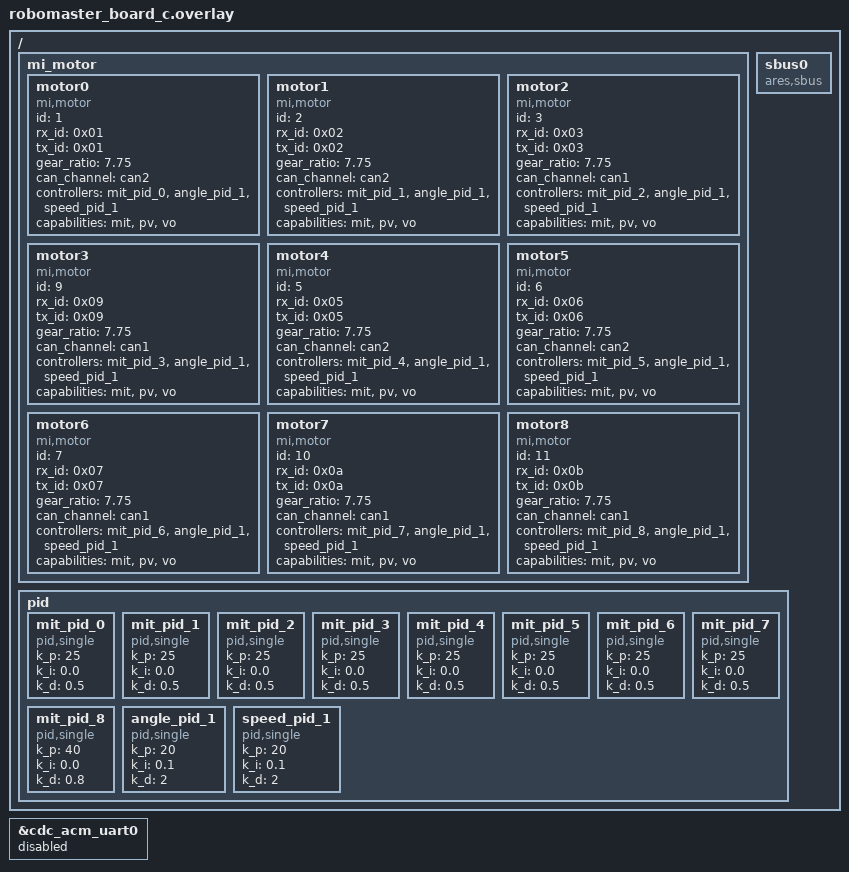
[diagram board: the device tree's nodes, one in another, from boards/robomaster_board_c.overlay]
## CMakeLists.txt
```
# SPDX-License-Identifier: Apache-2.0

cmake_minimum_required(VERSION 3.20.0)
set(CMAKE_CXX_STANDARD 17)
find_package(Zephyr REQUIRED HINTS $ENV{ZEPHYR_BASE})
project(legged)

FILE(GLOB app_sources src/*.c)

include_directories(${ZEPHYR_BASE}/include)
include_directories(${CMAKE_CURRENT_SOURCE_DIR}/include)
include_directories(${CMAKE_CURRENT_SOURCE_DIR}/dts)
target_sources(app PRIVATE ${app_sources})
target_include_directories(app PRIVATE ${ZEPHYR_BASE}/include)
target_include_directories(app PRIVATE ${CMAKE_CURRENT_SOURCE_DIR}/include)
target_include_directories(app PRIVATE ${CMAKE_CURRENT_SOURCE_DIR}/dts)
```

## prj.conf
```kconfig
#启用线程分析器
CONFIG_THREAD_ANALYZER=y
CONFIG_THREAD_ANALYZER_USE_LOG=y
CONFIG_THREAD_ANALYZER_USE_PRINTK=n
CONFIG_THREAD_NAME=y
# CONFIG_THREAD_ANALYZER_AUTO=y
# CONFIG_THREAD_ANALYZER_AUTO_INTERVAL=5
# CONFIG_THREAD_ANALYZER_LOG_LEVEL_INF=y
# CONFIG_THREAD_ANALYZER_AUTO_SEPARATE_CORES=n

# 启用 UART 控制台
CONFIG_UART_CONSOLE=y

# 禁用 SEGGER RTT
CONFIG_USE_SEGGER_RTT=n

# 启用事件支持
CONFIG_EVENTS=y

# 启用串行支持
CONFIG_SERIAL=y
CONFIG_SPI_ASYNC=y
# 禁用优化
CONFIG_NO_OPTIMIZATIONS=n

# 启用驱动
CONFIG_MOTOR=y
CONFIG_MOTOR_DJI=y
CONFIG_MOTOR_MI=y
CONFIG_MOTOR_LOG_LEVEL=4
CONFIG_CAN=y
CONFIG_MOTOR_INIT_PRIORITY=90
CONFIG_PID=y

CONFIG_ARES=y
CONFIG_ARES_SBUS=y
CONFIG_SBUS_INIT_PRIORITY=90

CONFIG_DMA=y
CONFIG_DMA_STM32=y  # STM32 DMA 驱动
CONFIG_UART_STM32=y # STM32 UART 驱动
# CONFIG_STM32_UART_DMA=y
CONFIG_AUTO_PROBE_GYRO_BIAS=y
CONFIG_EKF_LIB=y
# CONFIG_HAS_STM32CUBE=y
# CONFIG_USE_STM32_HAL_DMA=y
# CONFIG_SPI=y
# CONFIG_SPI_STM32=y

#
# Device Drivers
#
# CONFIG_SENSOR=y
# CONFIG_BMI08X=y
# CONFIG_BMI08X_ACCEL_TRIGGER_NONE is not set
# CONFIG_BMI08X_ACCEL_TRIGGER_GLOBAL_THREAD=y
# CONFIG_BMI08X_ACCEL_TRIGGER_OWN_THREAD is not set
# CONFIG_BMI08X_GYRO_TRIGGER_NONE is not set
# CONFIG_BMI08X_GYRO_TRIGGER_GLOBAL_THREAD=y
# CONFIG_BMI08X_GYRO_TRIGGER_OWN_THREAD is not set
# CONFIG_BMI08X_I2C_WRITE_BURST_SIZE=16

CONFIG_DEBUG_THREAD_INFO=y
CONFIG_MAIN_STACK_SIZE=4096

# ARES communication libraries
# CONFIG_EXPERIMENTAL_BULK_LIB=y
CONFIG_USB_BULK_INTERFACE=y
CONFIG_DUAL_PROPOSE_PROTOCOL=y

CONFIG_UDC_DRIVER_LOG_LEVEL_WRN=y
CONFIG_USBD_LOG_LEVEL_WRN=y

CONFIG_USBD_MAX_UDC_MSG=24
CONFIG_USBD_MSG_SLAB_COUNT=24
CONFIG_UDC_BUF_COUNT=128
CONFIG_UDC_WORKQUEUE=y
CONFIG_UDC_WORKQUEUE_PRIORITY=0
CONFIG_UDC_BUF_POOL_SIZE=4096
# Enable legacy USB device stack (provides usb_dc_ep_write)
# CONFIG_USB_DEVICE_STACK=y
# Set VID/PID for device; optional but good practice
# CONFIG_USB_DEVICE_VID=0x1209
# CONFIG_USB_DEVICE_PID=0x0001
```

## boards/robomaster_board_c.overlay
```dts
/ {
	mi_motor {
		motor0: motor0{
			compatible = "mi,motor";
			id = <1>;
			rx_id = <0x01>;
			tx_id = <0x01>;
			gear_ratio = "7.75";
			status = "okay";
			can_channel = <&can2>;
			controllers = <&mit_pid_0 &angle_pid_1 &speed_pid_1>;
			capabilities = "mit","pv", "vo";
		};

		motor1: motor1{
			compatible = "mi,motor";
			id = <2>;
			rx_id = <0x02>;
			tx_id = <0x02>;
			gear_ratio = "7.75";
			status = "okay";
			can_channel = <&can2>;
			controllers = <&mit_pid_1 &angle_pid_1 &speed_pid_1>;
			capabilities = "mit","pv", "vo";
		};

		motor2: motor2{
			compatible = "mi,motor";
			id = <3>;
			rx_id = <0x03>;
			tx_id = <0x03>;
			gear_ratio = "7.75";
			status = "okay";
			can_channel = <&can1>;
			controllers = <&mit_pid_2 &angle_pid_1 &speed_pid_1>;
			capabilities = "mit","pv", "vo";
		};

		motor3: motor3{
			compatible = "mi,motor";
			id = <9>;
			rx_id = <0x09>;
			tx_id = <0x09>;
			gear_ratio = "7.75";
			status = "okay";
			can_channel = <&can1>;
			controllers = <&mit_pid_3 &angle_pid_1 &speed_pid_1>;
			capabilities = "mit","pv", "vo";
		};
		
		motor4: motor4{
			compatible = "mi,motor";
			id = <5>;
			rx_id = <0x05>;
			tx_id = <0x05>;
			gear_ratio = "7.75";
			status = "okay";
			can_channel = <&can2>;
			controllers = <&mit_pid_4 &angle_pid_1 &speed_pid_1>;
			capabilities = "mit","pv", "vo";
		};

		motor5: motor5{
			compatible = "mi,motor";
			id = <6>;
			rx_id = <0x06>;
			tx_id = <0x06>;
			gear_ratio = "7.75";
			status = "okay";
			can_channel = <&can2>;
			controllers = <&mit_pid_5 &angle_pid_1 &speed_pid_1>;
			capabilities = "mit","pv", "vo";
		};

		motor6: motor6{
			compatible = "mi,motor";
			id = <7>;
			rx_id = <0x07>;
			tx_id = <0x07>;
			gear_ratio = "7.75";
			status = "okay";
			can_channel = <&can1>;
			controllers = <&mit_pid_6 &angle_pid_1 &speed_pid_1>;
			capabilities = "mit","pv", "vo";
		};

		motor7: motor7{
			compatible = "mi,motor";
			id = <10>;
			rx_id = <0x0a>;
			tx_id = <0x0a>;
			gear_ratio = "7.75";
			status = "okay";
			can_channel = <&can1>;
			controllers = <&mit_pid_7 &angle_pid_1 &speed_pid_1>;
			capabilities = "mit","pv", "vo";
		};
		motor8: motor8{
			compatible = "mi,motor";
			id = <11>;
			rx_id = <0x0b>;
			tx_id = <0x0b>;
			gear_ratio = "7.75";
			status = "okay";
			can_channel = <&can1>;
			controllers = <&mit_pid_8 &angle_pid_1 &speed_pid_1>;
			capabilities = "mit","pv", "vo";
		};
	};
	sbus0: sbus0 {
		compatible = "ares,sbus";
		status = "okay";
	};
	pid {
		mit_pid_0: mit_pid_0 {
			#controller-cells = <0>;
			compatible = "pid,single";
			k_p = "25";
			k_i = "0.0";
			k_d = "0.5";
		};
		mit_pid_1: mit_pid_1 {
			#controller-cells = <0>;
			compatible = "pid,single";
			k_p = "25";
			k_i = "0.0";
			k_d = "0.5";
		};
		mit_pid_2: mit_pid_2 {
			#controller-cells = <0>;
			compatible = "pid,single";
			k_p = "25";
			k_i = "0.0";
			k_d = "0.5";
		};
		mit_pid_3: mit_pid_3 {
			#controller-cells = <0>;
			compatible = "pid,single";
			k_p = "25";
			k_i = "0.0";
			k_d = "0.5";
		};
		mit_pid_4: mit_pid_4 {
			#controller-cells = <0>;
			compatible = "pid,single";
			k_p = "25";
			k_i = "0.0";
			k_d = "0.5";
		};
		mit_pid_5: mit_pid_5 {
			#controller-cells = <0>;
			compatible = "pid,single";
			k_p = "25";
			k_i = "0.0";
			k_d = "0.5";
		};
		mit_pid_6: mit_pid_6 {
			#controller-cells = <0>;
			compatible = "pid,single";
			k_p = "25";
			k_i = "0.0";
			k_d = "0.5";
		};
		mit_pid_7: mit_pid_7 {
			#controller-cells = <0>;
			compatible = "pid,single";
			k_p = "25";
			k_i = "0.0";
			k_d = "0.5";
		};
		mit_pid_8: mit_pid_8 {
			#controller-cells = <0>;
			compatible = "pid,single";
			k_p = "40";
			k_i = "0.0";
			k_d = "0.8";
		};
		
		angle_pid_1: angle_pid_1 {
			#controller-cells = <0>;
			compatible = "pid,single";
			k_p = "20";
			k_i = "0.1";
			k_d = "2";
		};
		speed_pid_1: speed_pid_1 {
			#controller-cells = <0>;
			compatible = "pid,single";
			k_p = "20";
			k_i = "0.1";
			k_d = "2";
		};
	};
};

&cdc_acm_uart0 {
	status = "disabled";
};
```

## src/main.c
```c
#include <math.h>
#include <stdbool.h>
#include <stddef.h>
#include <stdint.h>
#include <zephyr/device.h>
#include <zephyr/logging/log.h>
#include <zephyr/kernel.h>
#include <zephyr/drivers/motor.h>
#include <zephyr/drivers/sbus.h>
#include <ares/board/init.h>
#include <ares/ekf/imu_task.h>
#include <ares/ares_comm.h>
#include <ares/protocol/dual/dual_protocol.h>
#include "ares/ekf/QuaternionEKF.h"
#include <zephyr/debug/thread_analyzer.h>
#include <ares/interface/usb/usb_bulk.h>
#include <zephyr/drivers/gpio.h>
#include "main.h"
#include "ares/protocol/dual/dual_protocol.h"

LOG_MODULE_REGISTER(main, LOG_LEVEL_DBG);

#ifndef PI
#define PI 3.14159265358979323846f
#endif

#define STACK_SIZE 4096

#define RPM2RADPS(rpm) ((rpm) * (PI / 30.0f))
#define RADPS2RPM(radps) ((radps) * (30.0f / PI))
#define DEG2RAD(deg) ((deg) * (PI / 180.0f))
#define RAD2DEG(rad) ((rad) * (180.0f / PI))
/**
 * @brief 计算重力向量在地面坐标系中的单位化投影
 * @param q 四元数 [q0, q1, q2, q3] (归一化)
 * @param body_accel 载体坐标系下的加速度 [ax, ay, az]（未使用，保留接口兼容性）
 * @param g 重力加速度大小（未使用，保留接口兼容性）
 * @param gravity_projection 输出：重力向量在地面坐标系的单位化投影 [gx, gy, gz]
 */
void calculate_gravity_projection(float *q, float *body_accel, float g, float *gravity_projection)
{
    // 四元数转旋转矩阵公式
    float q0 = q[0], q1 = q[1], q2 = q[2], q3 = q[3];
    
    // 确保四元数是归一化的
    float qnorm = sqrtf(q0*q0 + q1*q1 + q2*q2 + q3*q3);
    if (qnorm > 0.0001f) {
        q0 /= qnorm; q1 /= qnorm; q2 /= qnorm; q3 /= qnorm;
    }
    
    // 载体坐标系各轴在重力方向上的投影
    // 即载体坐标系XYZ轴与重力向量（垂直向下）的夹角余弦值
    // 这等价于将载体坐标系的单位向量投影到重力方向上
    
    // 载体坐标系X轴在重力方向的投影 = 载体X轴与重力向量的点积
    // 载体X轴: [1,0,0] 变换到地面坐标系，然后与重力向量[0,0,-1]点积
    // 结果就是旋转矩阵第一行第三列的负值
    gravity_projection[0] = -(2 * (q1 * q3 + q0 * q2));  // 载体X轴在重力方向的投影
    
    // 载体坐标系Y轴在重力方向的投影
    gravity_projection[1] = -(2 * (q2 * q3 - q0 * q1));  // 载体Y轴在重力方向的投影
    
    // 载体坐标系Z轴在重力方向的投影  
    gravity_projection[2] = -(1 - 2 * (q1 * q1 + q2 * q2));  // 载体Z轴在重力方向的投影
    
    // 这些值的范围是[-1, 1]，表示各轴与重力方向的夹角余弦值
    // 当载体某轴与重力方向平行时，对应投影为±1
    // 当载体某轴与重力方向垂直时，对应投影为0
}

/**
 * @brief 计算四元数对应的欧拉角
 * @param q 四元数 [q0, q1, q2, q3]
 * @param euler 输出欧拉角 [roll, pitch, yaw] (弧度)
 */
void quaternion_to_euler(float *q, float *euler)
{
    float q0 = q[0], q1 = q[1], q2 = q[2], q3 = q[3];
    
    // Roll (绕X轴旋转)
    euler[0] = atan2f(2.0f * (q0 * q1 + q2 * q3), 1.0f - 2.0f * (q1 * q1 + q2 * q2));
    
    // Pitch (绕Y轴旋转)
    float sin_pitch = 2.0f * (q0 * q2 - q3 * q1);
    if (fabsf(sin_pitch) >= 1.0f) {
        euler[1] = copysignf(PI / 2.0f, sin_pitch); // 万向锁情况
    } else {
        euler[1] = asinf(sin_pitch);
    }
    
    // Yaw (绕Z轴旋转)
    euler[2] = atan2f(2.0f * (q0 * q3 + q1 * q2), 1.0f - 2.0f * (q2 * q2 + q3 * q3));
}
float kp_cmd[9] = {0};
float kd_cmd[9] = {0};
float action[9]= {0};
float torque_cmd[9] = {0};
float motor_angle[9] = {0};
float motor_speed[9] = {0};
float motor_torque[9] = {0};
float imu_pack[10] = {0};
float current_accel[3] = {0};  // 存储当前加速度数据
float sbus_data[11] = {0};
uint8_t actionbuf[36]= {0};
uint8_t torque_cmdbuf[36]= {0};
uint8_t anglebuf[36]= {0};
uint8_t speedbuf[36]= {0};
uint8_t torquebuf[36]= {0};
uint8_t imudatabuf[40]= {0};
uint8_t sbus_buf[44]= {0};
uint8_t kp_cmdbuf[36]= {0};
uint8_t kd_cmdbuf[36]= {0};
sync_table_t *angle_tx;
sync_table_t *speed_tx;
sync_table_t *torque_tx;
sync_table_t *imu_tx;
sync_table_t *sbus_tx;

struct pid_config new_config={.k_p = 25.0f, .k_d = 0.5f};
static int pub_cnt = 0;  // 添加发布计数器

DUAL_PROPOSE_PROTOCOL_DEFINE(dual_protocol);
ARES_BULK_INTERFACE_DEFINE(usb_bulk_interface);

// leg_motors leg1 = { motor1, motor2, LEFT_BACK};
// leg_motors leg2 = { motor3, motor4, LEFT_FRONT};
// leg_motors leg3 = { motor6, motor5, RIGHT_BACK};
// leg_motors leg4 = { motor8, motor7, RIGHT_FRONT};

const struct device *motors[9]={
    DEVICE_DT_GET(DT_NODELABEL(motor3)), DEVICE_DT_GET(DT_NODELABEL(motor2)), DEVICE_DT_GET(DT_NODELABEL(motor6)), DEVICE_DT_GET(DT_NODELABEL(motor7)), DEVICE_DT_GET(DT_NODELABEL(motor8)), DEVICE_DT_GET(DT_NODELABEL(motor1)), DEVICE_DT_GET(DT_NODELABEL(motor0)), DEVICE_DT_GET(DT_NODELABEL(motor4)), DEVICE_DT_GET(DT_NODELABEL(motor5))
};

const struct device *mit_pid[9] ={
    DEVICE_DT_GET(DT_NODELABEL(mit_pid_3)),
    DEVICE_DT_GET(DT_NODELABEL(mit_pid_2)),
    DEVICE_DT_GET(DT_NODELABEL(mit_pid_6)),
    DEVICE_DT_GET(DT_NODELABEL(mit_pid_7)),
    DEVICE_DT_GET(DT_NODELABEL(mit_pid_8)),
    DEVICE_DT_GET(DT_NODELABEL(mit_pid_1)),
    DEVICE_DT_GET(DT_NODELABEL(mit_pid_0)),
    DEVICE_DT_GET(DT_NODELABEL(mit_pid_4)),
    DEVICE_DT_GET(DT_NODELABEL(mit_pid_5)),
};

void stand(){
    motor_control(motor9, SET_ZERO);
    motor_set_mit(motor9, 0.0f, 0.0f, 0.0f);
    
    /* 渐进式移动到初始位置 */
    for(int i = 0; i < 10; i++) {
        float progress = (i + 1) * 0.1f;
        motor_set_mit(motor1, 0.0f, progress * INITIAL_ANGLE1, 0.0f);
        motor_set_mit(motor2, 0.0f, progress * INITIAL_ANGLE2, 0.0f);
        motor_set_mit(motor3, 0.0f, progress * INITIAL_ANGLE3, 0.0f);
        motor_set_mit(motor4, 0.0f, progress * INITIAL_ANGLE4, 0.0f);
        motor_set_mit(motor5, 0.0f, progress * INITIAL_ANGLE5, 0.0f);
        motor_set_mit(motor6, 0.0f, progress * INITIAL_ANGLE6, 0.0f);
        motor_set_mit(motor7, 0.0f, progress * INITIAL_ANGLE7, 0.0f);
        motor_set_mit(motor8, 0.0f, progress * INITIAL_ANGLE8, 0.0f);
        k_msleep(50);  // 增加延时确保平滑运动
    }
    
    k_sleep(K_MSEC(500));
    
    /* 重新设置零点并释放力矩 */
    for(int i = 0; i < 9; i++) {
        motor_control(motors[i], SET_ZERO);
        motor_set_mit(motors[i], 0.0f, 0.0f, 0.0f);
        k_sleep(K_MSEC(10));
    }
}

// void Sensor_update_cb(QEKF_INS_t *QEKF)
// {
//     pub_cnt++;
    
//     // 存储四元数
//     imu_pack[0] = QEKF->q[0];
//     imu_pack[1] = QEKF->q[1];
//     imu_pack[2] = QEKF->q[2];
//     imu_pack[3] = QEKF->q[3];

//     // 存储角速度  
//     imu_pack[4] = QEKF->Gyro[0];
//     imu_pack[5] = QEKF->Gyro[1];
//     imu_pack[6] = QEKF->Gyro[2];
//     // if(pub_cnt % 3000 == 0) {
//     //     LOG_ERR(" [%f, %f, %f, %f]", 
//     //         QEKF->q[0], QEKF->q[1], QEKF->q[2], QEKF->q[3]);
//     // }
    
//     // 存储当前加速度数据
//     current_accel[0] = QEKF->Accel[0];
//     current_accel[1] = QEKF->Accel[1]; 
//     current_accel[2] = QEKF->Accel[2];
    
//     k_work_submit_to_queue(&work_queue, &imu_tx_data_handle);
// }
int action_rx_cb(int status)
{
	// LOG_ERR("action_rx_cb called with status: %d", status);
	if(status == SYNC_PACK_STATUS_DONE) {
		k_work_submit_to_queue(&work_queue, &action_rx_data_handle);
	}else{
		return;
	}
	return 0;
}
int torque_cmd_rx_cb(int status)
{
    // LOG_ERR("torque_cmd_rx_cb called with status: %d", status);
	if(status == SYNC_PACK_STATUS_DONE) {
		k_work_submit_to_queue(&work_queue, &torque_cmd_rx_data_handle);
	}else{
		return 0;
	}
	return 0;
}

int kp_cmd_rx_cb(int status)
{
    // LOG_ERR("kp_cmd_rx_cb called with status: %d", status);
    if(status == SYNC_PACK_STATUS_DONE) {
     
        // LOG_ERR("kp_cmd: %f, %f, %f, %f, %f, %f, %f, %f, %f", 
        //         kp_cmd[0], kp_cmd[1], kp_cmd[2], kp_cmd[3], 
        //         kp_cmd[4], kp_cmd[5], kp_cmd[6], kp_cmd[7], kp_cmd[8]);
        memcpy(&kp_cmd, &kp_cmdbuf, 36);
        for(int i = 0; i < 9; i++) {
            new_config.k_p = kp_cmd[i];
        new_config.k_d = kd_cmd[i];
        pid_set_params(mit_pid[i], &new_config);
        }
    }else{
        return 0;
    }
    return 0;
}
int kd_cmd_rx_cb(int status)
{
    // LOG_ERR("kd_cmd_rx_cb called with status: %d", status);
    if(status == SYNC_PACK_STATUS_DONE) {
        // LOG_ERR("kd_cmd: %f, %f, %f, %f, %f, %f, %f, %f, %f", 
        //         kd_cmd[0], kd_cmd[1], kd_cmd[2], kd_cmd[3], 
        //         kd_cmd[4], kd_cmd[5], kd_cmd[6], kd_cmd[7], kd_cmd[8]);
        memcpy(&kd_cmd, &kd_cmdbuf, 36);
        for(int i = 0; i < 9; i++) {
            new_config.k_p = kp_cmd[i];
        new_config.k_d = kd_cmd[i];
        pid_set_params(mit_pid[i], &new_config);
        }
    }else{
        return 0;
    }
    return 0;
}
void imu_tx_data_handler(struct k_work *work)
{   
    // 计算重力向量在地面坐标系中的单位化投影
    static float gravity_projection[3] = {0};

    // 直接使用四元数计算重力投影（不需要加速度数据）
    calculate_gravity_projection(imu_pack, current_accel, 0, gravity_projection);
    
    // 上传重力向量在地面坐标系的单位化投影
    imu_pack[7] = gravity_projection[0];
    imu_pack[8] = gravity_projection[1];
    imu_pack[9] = gravity_projection[2];
    
    
    
    memcpy(imudatabuf, imu_pack, sizeof(imu_pack));
    dual_sync_flush(&dual_protocol, imu_tx);
}

void tx_isr_handler(struct k_timer *dummy)
{
	k_work_submit_to_queue(&work_queue, &tx_data_handle);
}
uint16_t log_cnt = 0;
void tx_data_handler(struct k_work *work)
{
    for(int i = 0; i < 9; i++) {
        motor_angle[i] = DEG2RAD(motor_get_angle(motors[i]));
    }
    memcpy(anglebuf, motor_angle, sizeof(motor_angle));
    dual_sync_flush(&dual_protocol, angle_tx);
    k_sleep(K_USEC(500));
    for(int i = 0; i < 9; i++) {
        motor_speed[i] = RPM2RADPS(motor_get_speed(motors[i]));
    }
    memcpy(speedbuf, motor_speed, sizeof(motor_speed));
    dual_sync_flush(&dual_protocol, speed_tx);
    k_sleep(K_USEC(500));
    for(int i = 0; i < 9; i++) {
        motor_torque[i] = (motor_get_torque(motors[i]));
    }
    memcpy(torquebuf, motor_torque, sizeof(motor_torque));
    dual_sync_flush(&dual_protocol, torque_tx);
    k_sleep(K_USEC(500));
    for(int i = 0; i < 11; i++) {
        sbus_data[i] = sbus_get_percent(sbus,i);
    }
    // if(log_cnt++ % 100 == 0) {
       
    // LOG_ERR("sbus_data: %f, %f, %f, %f, %f, %f, %f, %f, %f, %f, %f", 
    //         sbus_data[0], sbus_data[1], sbus_data[2], sbus_data[3], sbus_data[4], sbus_data[5], sbus_data[6], sbus_data[7], sbus_data[8], sbus_data[9], sbus_data[10]);}
    memcpy(sbus_buf, sbus_data, sizeof(sbus_data));
    dual_sync_flush(&dual_protocol, sbus_tx);
}
void action_rx_data_handler(struct k_work *work)
{
    memcpy(&action, &actionbuf, 36);
   
    for(int i = 0; i < 9; i++) {
        // float deg_value = fmaxf(fminf(RAD2DEG(action[i]), 70.0f), -70.0f);
        // if(i==4){
        //     deg_value = fmaxf(fminf(deg_value, 30.0f), -30.0f);
        // }

        motor_set_mit(motors[i], 0.0f, RAD2DEG(action[i]), torque_cmd[i]);

    }
}

void torque_cmd_rx_data_handler(struct k_work *work)
{
    memcpy(&torque_cmd, &torque_cmdbuf, 36);
    
    for(int i = 0; i < 9; i++) {
        // float deg_value = fmaxf(fminf(RAD2DEG(action[i]), 70.0f), -70.0f);
        // if(i==4){
        //     deg_value = fmaxf(fminf(deg_value, 30.0f), -30.0f);
        // }

        motor_set_mit(motors[i], 0.0f, RAD2DEG(action[i]), torque_cmd[i]);

    }

    
}



/* USB COMMUNICATION CONFIG END */

int main()
{
    /* USB COMMUNICATION INITIATION START */
    ares_bind_interface(&usb_bulk_interface, &dual_protocol);
    /*
    * 0x0201 : MCU -> Host  (MotorState-A)
    * 0x0101 : Host -> MCU  (MotorCmd)
    */
    // IMU_Sensor_trig_init(accel_dev, gyro_dev);
    // IMU_Sensor_set_update_cb(Sensor_update_cb);
    angle_tx = dual_sync_add(&dual_protocol, 0x0201, anglebuf, 36, NULL);
    speed_tx = dual_sync_add(&dual_protocol, 0x0202, speedbuf, 36, NULL);
    torque_tx = dual_sync_add(&dual_protocol, 0x0203, torquebuf, 36, NULL);
    imu_tx = dual_sync_add(&dual_protocol, 0x0301, imu_pack, 40, NULL);
    sbus_tx = dual_sync_add(&dual_protocol, 0x0400, sbus_buf, 44, NULL);
     for(int i = 0; i < 9; i++) {
        motor_control(motors[i], SET_ZERO);
        k_sleep(K_MSEC(1));
    }
    /* 设置所有电机为MIT模式 */
    for(int i = 0; i < 9; i++) {
        motor_set_mode(motors[i], MIT);
        k_sleep(K_MSEC(1));
    }
    k_sleep(K_MSEC(100));  // 等待电机模式设置完成
    for(int i = 0; i < 9; i++) {
        motor_control(motors[i], ENABLE_MOTOR);
        k_sleep(K_MSEC(1));
    }
    k_sleep(K_MSEC(100));
    LOG_INF("Executing stand sequence...");
    stand();
    LOG_INF("Stand sequence completed.");
    /* 初始化工作队列 */
    k_work_queue_init(&work_queue);
    k_work_queue_start(&work_queue, work_queue_stack, STACK_SIZE, -1, NULL);
    dual_sync_add(&dual_protocol, 0x0101, &actionbuf, 36, (dual_trans_cb_t)action_rx_cb);
    dual_sync_add(&dual_protocol, 0x0102, &torque_cmdbuf, 36, (dual_trans_cb_t)torque_cmd_rx_cb);
    dual_sync_add(&dual_protocol, 0x0100, &kp_cmdbuf, 36, (dual_trans_cb_t)kp_cmd_rx_cb);
    dual_sync_add(&dual_protocol, 0x0200, &kd_cmdbuf, 36, (dual_trans_cb_t)kd_cmd_rx_cb);
    /* 初始化定时器 */
    tx_timer.expiry_fn = tx_isr_handler;

    /* 启动数据传输定时器 */
    k_timer_start(&tx_timer, K_NO_WAIT, K_MSEC(10));
    while (1) {  
        LOG_INF("Main loop iteration - pub_cnt: %d", pub_cnt);
        k_msleep(2000);  // 减少日志输出频率

       
    }
}
```

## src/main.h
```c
#include <zephyr/device.h>
#include <zephyr/drivers/motor.h>
#define ANGLE_OUTER 30
#define ANGLE_INNER 60

#define STACK_SIZE 4096

#define INITIAL_ANGLE1 ANGLE_OUTER 
#define INITIAL_ANGLE2 -ANGLE_INNER
#define INITIAL_ANGLE3 -ANGLE_OUTER
#define INITIAL_ANGLE4 ANGLE_INNER
#define INITIAL_ANGLE5 ANGLE_INNER
#define INITIAL_ANGLE6 -ANGLE_OUTER
#define INITIAL_ANGLE7 -ANGLE_INNER
#define INITIAL_ANGLE8 ANGLE_OUTER

#define MOTOR1_NODE DT_INST(0, mi_motor)
#define MOTOR2_NODE DT_INST(1, mi_motor)
#define MOTOR3_NODE DT_INST(2, mi_motor)
#define MOTOR4_NODE DT_INST(3, mi_motor)
#define MOTOR5_NODE DT_INST(4, mi_motor)
#define MOTOR6_NODE DT_INST(5, mi_motor)
#define MOTOR7_NODE DT_INST(6, mi_motor)
#define MOTOR8_NODE DT_INST(7, mi_motor)
#define MOTOR9_NODE DT_INST(8, mi_motor)

const struct device *motor1 = DEVICE_DT_GET(MOTOR1_NODE);//left back external motor
const struct device *motor2 = DEVICE_DT_GET(MOTOR2_NODE);//left back internal motor
const struct device *motor3 = DEVICE_DT_GET(MOTOR3_NODE);//left front external motor
const struct device *motor4 = DEVICE_DT_GET(MOTOR4_NODE);//left front internal motor
const struct device *motor5 = DEVICE_DT_GET(MOTOR5_NODE);//right back internal motor
const struct device *motor6 = DEVICE_DT_GET(MOTOR6_NODE);//right back external motor
const struct device *motor7 = DEVICE_DT_GET(MOTOR7_NODE);//right front internal motor
const struct device *motor8 = DEVICE_DT_GET(MOTOR8_NODE);//right front external motor
const struct device *motor9 = DEVICE_DT_GET(MOTOR9_NODE);//waist motor

// #define ACCEL_NODE DT_NODELABEL(bmi08x_accel)
// extern const struct device *accel_dev;

// #define GYRO_NODE DT_NODELABEL(bmi08x_gyro)
// extern const struct device *gyro_dev;

// const struct device *accel_dev = DEVICE_DT_GET(ACCEL_NODE);
// const struct device *gyro_dev = DEVICE_DT_GET(GYRO_NODE);

#define SBUS_NODE DT_NODELABEL(sbus0)
const struct device *sbus = DEVICE_DT_GET(SBUS_NODE);

void imu_tx_data_handler(struct k_work *work);

void tx_isr_handler(struct k_timer *dummy);
void tx_data_handler(struct k_work *work);
void action_rx_data_handler(struct k_work *work);
void torque_cmd_rx_data_handler(struct k_work *work);
struct k_work_q work_queue;

K_THREAD_STACK_DEFINE(work_queue_stack, STACK_SIZE);

K_WORK_DEFINE(imu_tx_data_handle, imu_tx_data_handler);

K_WORK_DEFINE(tx_data_handle, tx_data_handler);

K_WORK_DEFINE(action_rx_data_handle, action_rx_data_handler);

K_WORK_DEFINE(torque_cmd_rx_data_handle, torque_cmd_rx_data_handler);

K_TIMER_DEFINE(tx_timer, tx_isr_handler, NULL);
```
